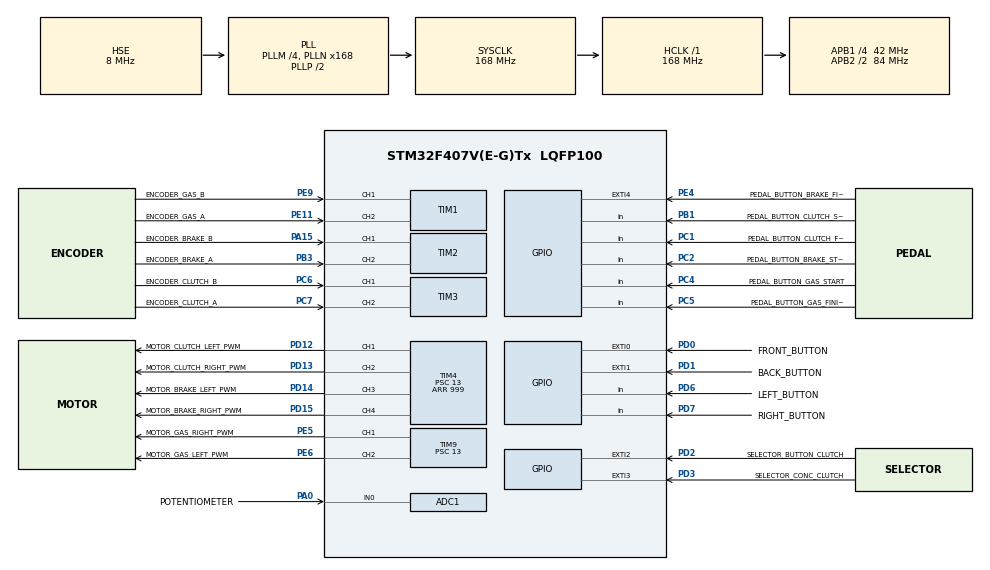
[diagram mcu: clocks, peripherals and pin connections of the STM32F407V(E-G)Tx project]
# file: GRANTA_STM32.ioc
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ADC1.Channel-0\#ChannelRegularConversion=ADC_CHANNEL_0
ADC1.NbrOfConversionFlag=1
ADC1.Rank-0\#ChannelRegularConversion=1
ADC1.SamplingTime-0\#ChannelRegularConversion=ADC_SAMPLETIME_3CYCLES
ADC1.master=1
Mcu.Family=STM32F4
Mcu.Name=STM32F407V(E-G)Tx
Mcu.Package=LQFP100
NVIC.EXTI0_IRQn=true\:0\:0\:false\:false\:true\:true\:true\:true
NVIC.EXTI1_IRQn=true\:0\:0\:false\:false\:true\:true\:true\:true
NVIC.EXTI2_IRQn=true\:0\:0\:false\:false\:true\:true\:true\:true
NVIC.EXTI3_IRQn=true\:0\:0\:false\:false\:true\:true\:true\:true
NVIC.EXTI4_IRQn=true\:0\:0\:false\:false\:true\:true\:true\:true
NVIC.PriorityGroup=NVIC_PRIORITYGROUP_4
NVIC.TIM5_IRQn=true\:0\:0\:false\:false\:true\:true\:true\:true
PA0-WKUP.GPIO_Label=POTENTIOMETER
PA0-WKUP.Signal=SharedAnalog_PA0
PA13.Mode=Serial_Wire
PA13.Signal=SYS_JTMS-SWDIO
PA14.Mode=Serial_Wire
PA14.Signal=SYS_JTCK-SWCLK
PA15.GPIO_Label=ENCODER_BRAKE_B
PA15.Signal=S_TIM2_CH1_ETR
PB1.GPIO_Label=PEDAL_BUTTON_CLUTCH_START
PB1.Signal=GPIO_Input
PB3.GPIO_Label=ENCODER_BRAKE_A
PB3.Signal=S_TIM2_CH2
PC1.GPIO_Label=PEDAL_BUTTON_CLUTCH_FINISH
PC1.Signal=GPIO_Input
PC2.GPIO_Label=PEDAL_BUTTON_BRAKE_START
PC2.Signal=GPIO_Input
PC4.GPIO_Label=PEDAL_BUTTON_GAS_START
PC4.Signal=GPIO_Input
PC5.GPIO_Label=PEDAL_BUTTON_GAS_FINISH
PC5.Signal=GPIO_Input
PC6.GPIO_Label=ENCODER_CLUTCH_B
PC6.Signal=S_TIM3_CH1
PC7.GPIO_Label=ENCODER_CLUTCH_A
PC7.Signal=S_TIM3_CH2
PD0.GPIO_Label=FRONT_BUTTON
PD0.GPIO_ModeDefaultEXTI=GPIO_MODE_IT_RISING_FALLING
PD0.GPIO_PuPd=GPIO_PULLDOWN
PD0.Signal=GPXTI0
PD1.GPIO_Label=BACK_BUTTON
PD1.GPIO_ModeDefaultEXTI=GPIO_MODE_IT_RISING_FALLING
PD1.GPIO_PuPd=GPIO_PULLDOWN
PD1.Signal=GPXTI1
PD12.GPIO_Label=MOTOR_CLUTCH_LEFT_PWM
PD12.Signal=S_TIM4_CH1
PD13.GPIO_Label=MOTOR_CLUTCH_RIGHT_PWM
PD13.Signal=S_TIM4_CH2
PD14.GPIO_Label=MOTOR_BRAKE_LEFT_PWM
PD14.Signal=S_TIM4_CH3
PD15.GPIO_Label=MOTOR_BRAKE_RIGHT_PWM
PD15.Signal=S_TIM4_CH4
PD2.GPIO_Label=SELECTOR_BUTTON_CLUTCH
PD2.GPIO_ModeDefaultEXTI=GPIO_MODE_IT_RISING_FALLING
PD2.GPIO_PuPd=GPIO_PULLDOWN
PD2.Signal=GPXTI2
PD3.GPIO_Label=SELECTOR_CONC_CLUTCH
PD3.GPIO_ModeDefaultEXTI=GPIO_MODE_IT_RISING_FALLING
PD3.GPIO_PuPd=GPIO_PULLDOWN
PD3.Signal=GPXTI3
PD6.GPIO_Label=LEFT_BUTTON
PD6.GPIO_PuPd=GPIO_PULLDOWN
PD6.Signal=GPIO_Input
PD7.GPIO_Label=RIGHT_BUTTON
PD7.GPIO_PuPd=GPIO_PULLDOWN
PD7.Signal=GPIO_Input
PE11.GPIO_Label=ENCODER_GAS_A
PE11.Signal=S_TIM1_CH2
PE4.GPIO_Label=PEDAL_BUTTON_BRAKE_FINISH
PE4.GPIO_ModeDefaultEXTI=GPIO_MODE_IT_RISING_FALLING
PE4.GPIO_PuPd=GPIO_PULLDOWN
PE4.Signal=GPXTI4
PE5.GPIO_Label=MOTOR_GAS_RIGHT_PWM
PE5.Signal=S_TIM9_CH1
PE6.GPIO_Label=MOTOR_GAS_LEFT_PWM
PE6.Signal=S_TIM9_CH2
PE9.GPIO_Label=ENCODER_GAS_B
PE9.Signal=S_TIM1_CH1
PH0-OSC_IN.Mode=HSE-External-Oscillator
PH0-OSC_IN.Signal=RCC_OSC_IN
PH1-OSC_OUT.Mode=HSE-External-Oscillator
PH1-OSC_OUT.Signal=RCC_OSC_OUT
ProjectManager.HeapSize=0x200
ProjectManager.StackSize=0x400
ProjectManager.TargetToolchain=STM32CubeIDE
RCC.48MHZClocksFreq_Value=84000000
RCC.AHBFreq_Value=168000000
RCC.APB1CLKDivider=RCC_HCLK_DIV4
RCC.APB1Freq_Value=42000000
RCC.APB1TimFreq_Value=84000000
RCC.APB2CLKDivider=RCC_HCLK_DIV2
RCC.APB2Freq_Value=84000000
RCC.APB2TimFreq_Value=168000000
RCC.CortexFreq_Value=168000000
RCC.HCLKFreq_Value=168000000
RCC.HSE_VALUE=8000000
RCC.HSI_VALUE=16000000
RCC.LSE_VALUE=32768
RCC.PLLM=4
RCC.PLLN=168
RCC.PLLSourceVirtual=RCC_PLLSOURCE_HSE
RCC.SYSCLKFreq_VALUE=168000000
RCC.SYSCLKSource=RCC_SYSCLKSOURCE_PLLCLK
RCC.VCOOutputFreq_Value=336000000
SH.S_TIM1_CH1.0=TIM1_CH1,Encoder_Interface
SH.S_TIM1_CH2.0=TIM1_CH2,Encoder_Interface
SH.S_TIM2_CH1_ETR.0=TIM2_CH1,Encoder_Interface
SH.S_TIM2_CH2.0=TIM2_CH2,Encoder_Interface
SH.S_TIM3_CH1.0=TIM3_CH1,Encoder_Interface
SH.S_TIM3_CH2.0=TIM3_CH2,Encoder_Interface
SH.S_TIM4_CH1.0=TIM4_CH1,PWM Generation1 CH1
SH.S_TIM4_CH2.0=TIM4_CH2,PWM Generation2 CH2
SH.S_TIM4_CH3.0=TIM4_CH3,PWM Generation3 CH3
SH.S_TIM4_CH4.0=TIM4_CH4,PWM Generation4 CH4
SH.S_TIM9_CH1.0=TIM9_CH1,PWM Generation1 CH1
SH.S_TIM9_CH2.0=TIM9_CH2,PWM Generation2 CH2
SH.SharedAnalog_PA0.0=GPIO_Analog
SH.SharedAnalog_PA0.1=ADC1_IN0,IN0
TIM4.Channel-PWM\ Generation1\ CH1=TIM_CHANNEL_1
TIM4.Channel-PWM\ Generation2\ CH2=TIM_CHANNEL_2
TIM4.Channel-PWM\ Generation3\ CH3=TIM_CHANNEL_3
TIM4.Channel-PWM\ Generation4\ CH4=TIM_CHANNEL_4
TIM4.Period=999
TIM4.Prescaler=13
TIM5.Period=9999
TIM5.Prescaler=167
TIM9.Channel-PWM\ Generation1\ CH1=TIM_CHANNEL_1
TIM9.Channel-PWM\ Generation2\ CH2=TIM_CHANNEL_2
TIM9.Period=999
TIM9.Prescaler=13
VP_TIM5_VS_ClockSourceITR.Mode=TriggerSource_ITR0
board=custom

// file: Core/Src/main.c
/* USER CODE BEGIN Header */
/**
  ******************************************************************************
  * @file           : main.c
  * @brief          : Main program body
  ******************************************************************************
  * @attention
  *
  * Copyright (c) 2024 STMicroelectronics.
  * All rights reserved.
  *
  * This software is licensed under terms that can be found in the LICENSE file
  * in the root directory of this software component.
  * If no LICENSE file comes with this software, it is provided AS-IS.
  *
  ******************************************************************************
  */
/* USER CODE END Header */
#include "main.h"
#include "adc.h"
#include "tim.h"
#include "gpio.h"

/* USER CODE BEGIN Includes */
#include "pedals.h"
/* USER CODE END Includes */

void SystemClock_Config(void);

int main(void)
{

  /* MCU Configuration--------------------------------------------------------*/

  /* Reset of all peripherals, Initializes the Flash interface and the Systick. */
  HAL_Init();

  /* Configure the system clock */
  SystemClock_Config();

  /* Initialize all configured peripherals */
  MX_GPIO_Init();
  MX_TIM1_Init();
  MX_TIM2_Init();
  MX_TIM3_Init();
  MX_TIM4_Init();
  MX_TIM9_Init();
  MX_ADC1_Init();
  MX_TIM5_Init();
  /* USER CODE BEGIN 2 */
  HAL_TIM_Base_Start_IT(&htim5);

  HAL_TIM_Encoder_Start(&htim3, TIM_CHANNEL_1);
  HAL_TIM_Encoder_Start(&htim3, TIM_CHANNEL_2);

  clutch_initialize();
  /* USER CODE END 2 */

  /* Infinite loop */
  while (1)
  {

  }
}

void SystemClock_Config(void)
{
  RCC_OscInitTypeDef RCC_OscInitStruct = {0};
  RCC_ClkInitTypeDef RCC_ClkInitStruct = {0};

  /** Configure the main internal regulator output voltage
  */
  __HAL_RCC_PWR_CLK_ENABLE();
  __HAL_PWR_VOLTAGESCALING_CONFIG(PWR_REGULATOR_VOLTAGE_SCALE1);

  /** Initializes the RCC Oscillators according to the specified parameters
  * in the RCC_OscInitTypeDef structure.
  */
  RCC_OscInitStruct.OscillatorType = RCC_OSCILLATORTYPE_HSE;
  RCC_OscInitStruct.HSEState = RCC_HSE_ON;
  RCC_OscInitStruct.PLL.PLLState = RCC_PLL_ON;
  RCC_OscInitStruct.PLL.PLLSource = RCC_PLLSOURCE_HSE;
  RCC_OscInitStruct.PLL.PLLM = 4;
  RCC_OscInitStruct.PLL.PLLN = 168;
  RCC_OscInitStruct.PLL.PLLP = RCC_PLLP_DIV2;
  RCC_OscInitStruct.PLL.PLLQ = 4;
  if (HAL_RCC_OscConfig(&RCC_OscInitStruct) != HAL_OK)
  {
    Error_Handler();
  }

  /** Initializes the CPU, AHB and APB buses clocks
  */
  RCC_ClkInitStruct.ClockType = RCC_CLOCKTYPE_HCLK|RCC_CLOCKTYPE_SYSCLK
                              |RCC_CLOCKTYPE_PCLK1|RCC_CLOCKTYPE_PCLK2;
  RCC_ClkInitStruct.SYSCLKSource = RCC_SYSCLKSOURCE_PLLCLK;
  RCC_ClkInitStruct.AHBCLKDivider = RCC_SYSCLK_DIV1;
  RCC_ClkInitStruct.APB1CLKDivider = RCC_HCLK_DIV4;
  RCC_ClkInitStruct.APB2CLKDivider = RCC_HCLK_DIV2;

  if (HAL_RCC_ClockConfig(&RCC_ClkInitStruct, FLASH_LATENCY_5) != HAL_OK)
  {
    Error_Handler();
  }
}

void Error_Handler(void)
{
  __disable_irq();
  while (1)
  {
  }
}
